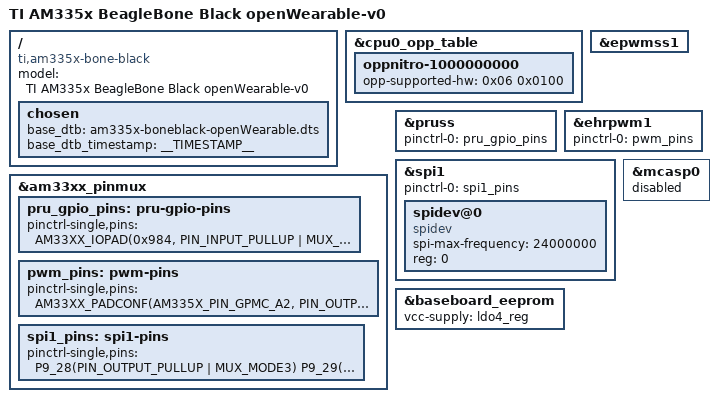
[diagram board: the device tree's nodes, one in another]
// SPDX-License-Identifier: GPL-2.0-only
/*
 * Copyright (C) 2012 Texas Instruments Incorporated - https://www.ti.com/
 */
/dts-v1/;

#include "am33xx.dtsi"
#include "am335x-bone-common.dtsi"
#include "am335x-boneblack-common.dtsi"

/ {
	model = "TI AM335x BeagleBone Black openWearable-v0";
	compatible = "ti,am335x-bone-black", "ti,am335x-bone", "ti,am33xx";

	chosen {
		base_dtb = "am335x-boneblack-openWearable.dts";
		base_dtb_timestamp = __TIMESTAMP__;
	};

};

&cpu0_opp_table {
	/*
	 * All PG 2.0 silicon may not support 1GHz but some of the early
	 * BeagleBone Blacks have PG 2.0 silicon which is guaranteed
	 * to support 1GHz OPP so enable it for PG 2.0 on this board.
	 */
	oppnitro-1000000000 {
		opp-supported-hw = <0x06 0x0100>;
	};
};



&am33xx_pinmux {
	pru_gpio_pins: pru-gpio-pins {
		pinctrl-single,pins = <
			AM33XX_IOPAD(0x984, PIN_INPUT_PULLUP | MUX_MODE6)	      /* P9.24, MODE5, pr1_pru0_pru_r31_16 */

			AM33XX_IOPAD(0x9ac, PIN_OUTPUT_PULLDOWN | MUX_MODE5)	  /* P9.25, MODE5, pr1_pru0_pru_r30_7 */
			AM33XX_IOPAD(0x9a4, PIN_OUTPUT_PULLDOWN | MUX_MODE5)	  /* P9.27, MODE5, pr1_pru0_pru_r30_5 */
			AM33XX_IOPAD(0x9a8, PIN_OUTPUT_PULLDOWN | MUX_MODE5)	  /* P9.41, MODE5, pr1_pru0_pru_r30_6 */
			AM33XX_IOPAD(0x9b4, PIN_INPUT)	                        /* Unused P.41 */
			AM33XX_IOPAD(0x9a0, PIN_OUTPUT_PULLDOWN | MUX_MODE5)	  /* P9.42, MODE5, pr1_pru0_pru_r30_4 */
			AM33XX_IOPAD(0x964, PIN_INPUT)	                        /* Unused P.42 */

			AM33XX_IOPAD(0x8a0, PIN_OUTPUT_PULLDOWN | MUX_MODE5)	  /* P8.45, MODE5, pr1_pru1_pru_r30_0 */
			AM33XX_IOPAD(0x8a4, PIN_OUTPUT_PULLDOWN | MUX_MODE5)	  /* P8.46, MODE5, pr1_pru1_pru_r30_1 */
			AM33XX_IOPAD(0x8a8, PIN_OUTPUT_PULLDOWN | MUX_MODE5)	  /* P8.43, MODE5, pr1_pru1_pru_r30_2 */
			AM33XX_IOPAD(0x8ac, PIN_OUTPUT_PULLDOWN | MUX_MODE5)	  /* P8.44, MODE5, pr1_pru1_pru_r30_3 */

			AM33XX_IOPAD(0x8b0, PIN_INPUT_PULLUP | MUX_MODE6)	      /* P8.41, MODE6, pr1_pru1_pru_r31_4 */
			AM33XX_IOPAD(0x8b4, PIN_INPUT_PULLUP | MUX_MODE6)       /* P8.42, MODE6, pr1_pru1_pru_r31_5 */
			AM33XX_IOPAD(0x8b8, PIN_INPUT_PULLUP | MUX_MODE6)	      /* P8.39, MODE6, pr1_pru1_pru_r31_6 */
			AM33XX_IOPAD(0x8bc, PIN_INPUT_PULLUP | MUX_MODE6)	      /* P8.40, MODE6, pr1_pru1_pru_r31_7 */
		>;
	};

  pwm_pins: pwm-pins {
		pinctrl-single,pins = <
			AM33XX_PADCONF(AM335X_PIN_GPMC_A2, PIN_OUTPUT_PULLDOWN, MUX_MODE6)	/* P9_14: gpmc_a2.ehrpwm1a */
    >;
  };

  spi1_pins: spi1-pins {
    pinctrl-single,pins = <
      P9_28(PIN_OUTPUT_PULLUP | MUX_MODE3)  /* P9.28 - spi1_cs0,  MODE3 | OUTPUT_PULLUP */
      P9_29(PIN_INPUT_PULLUP | MUX_MODE3)   /* P9.29 - spi1_d0, MODE3 | INPUT_PULLUP */
      P9_30(PIN_OUTPUT_PULLUP | MUX_MODE3)  /* P9.30 - spi1_d1, MODE3 | OUTPUT_PULLUP */
      P9_31(PIN_INPUT_PULLUP | MUX_MODE3)   /* P9.31 - spi1_sclk, MODE3 | INPUT_PULLUP */
    >;
  };
};


&pruss {
    pinctrl-names = "default";
    pinctrl-0 = <&pru_gpio_pins>;
    status = "okay";
};

&epwmss1 {
	status = "okay";
};


&ehrpwm1 {
	pinctrl-names = "default";
	pinctrl-0 = <&pwm_pins>;
	status = "okay";
};

&spi1 {
  pinctrl-names = "default";
  pinctrl-0 = <&spi1_pins>;
  status = "okay";
    spidev@0 {
      spi-max-frequency = <24000000>;
      reg = <0>;
      compatible = "spidev";
    };
};




/* Disable the following nodes due to pin mux conflicts with
 * PRU Software UART signals
 */
&mcasp0 {
	status = "disabled";
};

&baseboard_eeprom {
	vcc-supply = <&ldo4_reg>;
};
